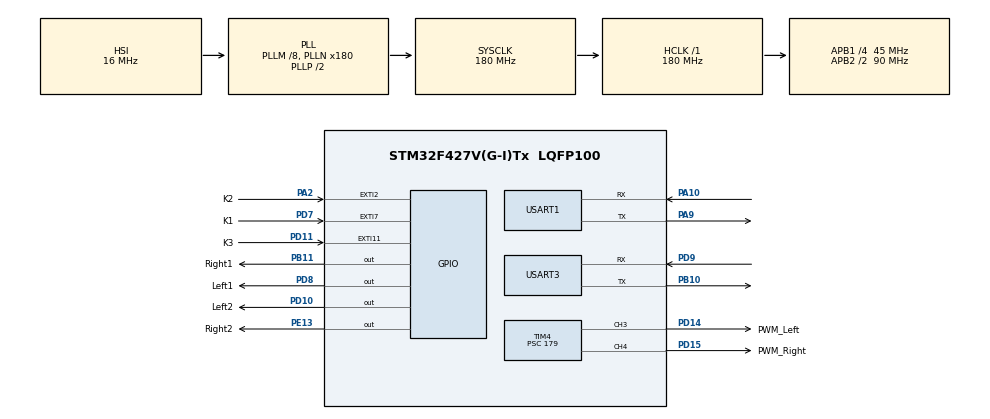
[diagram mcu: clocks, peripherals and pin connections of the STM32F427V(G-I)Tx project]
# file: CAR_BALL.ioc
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Mcu.Family=STM32F4
Mcu.Name=STM32F427V(G-I)Tx
Mcu.Package=LQFP100
NVIC.EXTI15_10_IRQn=true\:1\:0\:true\:false\:true\:true\:true\:true
NVIC.EXTI2_IRQn=true\:0\:0\:false\:false\:true\:true\:true\:true
NVIC.EXTI9_5_IRQn=true\:0\:0\:false\:false\:true\:true\:true\:true
NVIC.PriorityGroup=NVIC_PRIORITYGROUP_4
NVIC.TIM6_DAC_IRQn=true\:2\:0\:true\:false\:true\:true\:true\:true
NVIC.TIM7_IRQn=true\:1\:0\:true\:false\:true\:true\:true\:true
NVIC.USART1_IRQn=true\:0\:0\:false\:false\:true\:true\:true\:true
NVIC.USART3_IRQn=true\:0\:0\:false\:false\:true\:true\:true\:true
PA0/WKUP.Mode=SYS_WakeUp0
PA0/WKUP.Signal=SYS_WKUP
PA10.Mode=Asynchronous
PA10.Signal=USART1_RX
PA13.Mode=Serial_Wire
PA13.Signal=SYS_JTMS-SWDIO
PA14.Mode=Serial_Wire
PA14.Signal=SYS_JTCK-SWCLK
PA2.GPIO_Label=K2
PA2.GPIO_ModeDefaultEXTI=GPIO_MODE_IT_FALLING
PA2.GPIO_PuPd=GPIO_PULLUP
PA2.Signal=GPXTI2
PA9.Mode=Asynchronous
PA9.Signal=USART1_TX
PB10.Mode=Asynchronous
PB10.Signal=USART3_TX
PB11.GPIO_Label=Right1
PB11.GPIO_PuPd=GPIO_PULLUP
PB11.GPIO_Speed=GPIO_SPEED_FREQ_VERY_HIGH
PB11.Signal=GPIO_Output
PD10.GPIO_Label=Left2
PD10.GPIO_PuPd=GPIO_PULLUP
PD10.GPIO_Speed=GPIO_SPEED_FREQ_VERY_HIGH
PD10.Signal=GPIO_Output
PD11.GPIO_Label=K3
PD11.GPIO_ModeDefaultEXTI=GPIO_MODE_IT_FALLING
PD11.GPIO_PuPd=GPIO_PULLUP
PD11.Signal=GPXTI11
PD14.GPIO_Label=PWM_Left
PD14.Signal=S_TIM4_CH3
PD15.GPIO_Label=PWM_Right
PD15.Signal=S_TIM4_CH4
PD7.GPIO_Label=K1
PD7.GPIO_ModeDefaultEXTI=GPIO_MODE_IT_FALLING
PD7.GPIO_PuPd=GPIO_PULLUP
PD7.Signal=GPXTI7
PD8.GPIO_Label=Left1
PD8.GPIO_PuPd=GPIO_PULLUP
PD8.GPIO_Speed=GPIO_SPEED_FREQ_VERY_HIGH
PD8.Signal=GPIO_Output
PD9.Mode=Asynchronous
PD9.Signal=USART3_RX
PE13.GPIO_Label=Right2
PE13.GPIO_PuPd=GPIO_PULLUP
PE13.GPIO_Speed=GPIO_SPEED_FREQ_VERY_HIGH
PE13.Signal=GPIO_Output
PH0/OSC_IN.Mode=HSE-External-Oscillator
PH0/OSC_IN.Signal=RCC_OSC_IN
PH1/OSC_OUT.Mode=HSE-External-Oscillator
PH1/OSC_OUT.Signal=RCC_OSC_OUT
ProjectManager.HeapSize=0x200
ProjectManager.StackSize=0x400
ProjectManager.TargetToolchain=MDK-ARM V5.32
RCC.48MHZClocksFreq_Value=90000000
RCC.AHBFreq_Value=180000000
RCC.APB1CLKDivider=RCC_HCLK_DIV4
RCC.APB1Freq_Value=45000000
RCC.APB1TimFreq_Value=90000000
RCC.APB2CLKDivider=RCC_HCLK_DIV2
RCC.APB2Freq_Value=90000000
RCC.APB2TimFreq_Value=180000000
RCC.CortexFreq_Value=180000000
RCC.HCLKFreq_Value=180000000
RCC.HSE_VALUE=25000000
RCC.HSI_VALUE=16000000
RCC.LSE_VALUE=32768
RCC.PLLM=8
RCC.PLLN=180
RCC.SYSCLKFreq_VALUE=180000000
RCC.SYSCLKSource=RCC_SYSCLKSOURCE_PLLCLK
RCC.VCOOutputFreq_Value=360000000
SH.S_TIM4_CH3.0=TIM4_CH3,PWM Generation3 CH3
SH.S_TIM4_CH4.0=TIM4_CH4,PWM Generation4 CH4
TIM4.AutoReloadPreload=TIM_AUTORELOAD_PRELOAD_ENABLE
TIM4.Channel-PWM\ Generation3\ CH3=TIM_CHANNEL_3
TIM4.Channel-PWM\ Generation4\ CH4=TIM_CHANNEL_4
TIM4.Period=99
TIM4.Prescaler=179
TIM6.AutoReloadPreload=TIM_AUTORELOAD_PRELOAD_ENABLE
TIM6.Period=999
TIM6.Prescaler=8999
TIM7.AutoReloadPreload=TIM_AUTORELOAD_PRELOAD_ENABLE
TIM7.Period=4999
TIM7.Prescaler=8999
USART1.VirtualMode=VM_ASYNC
USART3.VirtualMode=VM_ASYNC
VP_TIM4_VS_ClockSourceINT.Mode=Internal
VP_TIM6_VS_ClockSourceINT.Mode=Enable_Timer
VP_TIM7_VS_ClockSourceINT.Mode=Enable_Timer
board=custom

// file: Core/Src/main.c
/* USER CODE BEGIN Header */
/**
  ******************************************************************************
  * @file           : main.c
  * @brief          : Main program body
  ******************************************************************************
  * @attention
  *
  * Copyright (c) 2025 STMicroelectronics.
  * All rights reserved.
  *
  * This software is licensed under terms that can be found in the LICENSE file
  * in the root directory of this software component.
  * If no LICENSE file comes with this software, it is provided AS-IS.
  *
  ******************************************************************************
  */
/* USER CODE END Header */
#include "main.h"
#include "tim.h"
#include "usart.h"
#include "gpio.h"

/* USER CODE BEGIN Includes */
#include "control.h"
/* USER CODE END Includes */

void SystemClock_Config(void);

int main(void)
{

  /* MCU Configuration--------------------------------------------------------*/

  /* Reset of all peripherals, Initializes the Flash interface and the Systick. */
  HAL_Init();

  /* Configure the system clock */
  SystemClock_Config();

  /* Initialize all configured peripherals */
  MX_GPIO_Init();
  MX_USART1_UART_Init();
  MX_USART3_UART_Init();
  MX_TIM6_Init();
  MX_TIM4_Init();
  MX_TIM7_Init();
  /* USER CODE BEGIN 2 */
	ALL_Init();
  /* USER CODE END 2 */

  /* Infinite loop */
  /* USER CODE BEGIN WHILE */
  while (1)
  {
	 //car_control();
    /* USER CODE END WHILE */

  }
}

void SystemClock_Config(void)
{
  RCC_OscInitTypeDef RCC_OscInitStruct = {0};
  RCC_ClkInitTypeDef RCC_ClkInitStruct = {0};

  /** Configure the main internal regulator output voltage
  */
  __HAL_RCC_PWR_CLK_ENABLE();
  __HAL_PWR_VOLTAGESCALING_CONFIG(PWR_REGULATOR_VOLTAGE_SCALE1);

  /** Initializes the RCC Oscillators according to the specified parameters
  * in the RCC_OscInitTypeDef structure.
  */
  RCC_OscInitStruct.OscillatorType = RCC_OSCILLATORTYPE_HSI;
  RCC_OscInitStruct.HSIState = RCC_HSI_ON;
  RCC_OscInitStruct.HSICalibrationValue = RCC_HSICALIBRATION_DEFAULT;
  RCC_OscInitStruct.PLL.PLLState = RCC_PLL_ON;
  RCC_OscInitStruct.PLL.PLLSource = RCC_PLLSOURCE_HSI;
  RCC_OscInitStruct.PLL.PLLM = 8;
  RCC_OscInitStruct.PLL.PLLN = 180;
  RCC_OscInitStruct.PLL.PLLP = RCC_PLLP_DIV2;
  RCC_OscInitStruct.PLL.PLLQ = 4;
  if (HAL_RCC_OscConfig(&RCC_OscInitStruct) != HAL_OK)
  {
    Error_Handler();
  }

  /** Activate the Over-Drive mode
  */
  if (HAL_PWREx_EnableOverDrive() != HAL_OK)
  {
    Error_Handler();
  }

  /** Initializes the CPU, AHB and APB buses clocks
  */
  RCC_ClkInitStruct.ClockType = RCC_CLOCKTYPE_HCLK|RCC_CLOCKTYPE_SYSCLK
                              |RCC_CLOCKTYPE_PCLK1|RCC_CLOCKTYPE_PCLK2;
  RCC_ClkInitStruct.SYSCLKSource = RCC_SYSCLKSOURCE_PLLCLK;
  RCC_ClkInitStruct.AHBCLKDivider = RCC_SYSCLK_DIV1;
  RCC_ClkInitStruct.APB1CLKDivider = RCC_HCLK_DIV4;
  RCC_ClkInitStruct.APB2CLKDivider = RCC_HCLK_DIV2;

  if (HAL_RCC_ClockConfig(&RCC_ClkInitStruct, FLASH_LATENCY_5) != HAL_OK)
  {
    Error_Handler();
  }
}

void Error_Handler(void)
{
  __disable_irq();
  while (1)
  {
  }
}
